# CC3200 register map
Vendor: Texas Instruments; Series: SimpleLink; File version: 1.0
CPU: CM4 r0p1, little endian, MPU, no FPU, 3 interrupt priority bits
Registers are 32-bit, read-write, reset 0x0 unless marked. A register's access mark holds for its fields unless they carry their own. Offsets are from the block's base; [hi:lo] are bit positions; {n}, {i} and the like mark numbered series.

## OCP_SHARED
Base 0x4402E000
0x00 SEMAPHORE1 — OCP_SHARED_SEMAPHORE1
  [1:0] MEM_SEMAPHORE1_M — OCP_SHARED_SEMAPHORE1
  [1:0] _MEM_SEMAPHORE10_M — OCP_SHARED_SEMAPHORE1
  [1:0] _MEM_SEMAPHORE11_M — OCP_SHARED_SEMAPHORE1
  [1:0] _MEM_SEMAPHORE12_M — OCP_SHARED_SEMAPHORE1
0x04 SEMAPHORE2 — OCP_SHARED_SEMAPHORE2
  [1:0] MEM_SEMAPHORE2_M
0x08 SEMAPHORE3 — OCP_SHARED_SEMAPHORE3
  [1:0] MEM_SEMAPHORE3_M
0x0C SEMAPHORE4 — OCP_SHARED_SEMAPHORE4
  [1:0] MEM_SEMAPHORE4_M
0x10 SEMAPHORE5 — OCP_SHARED_SEMAPHORE5
  [1:0] MEM_SEMAPHORE5_M
0x14 SEMAPHORE6 — OCP_SHARED_SEMAPHORE6
  [1:0] MEM_SEMAPHORE6_M
0x18 SEMAPHORE7 — OCP_SHARED_SEMAPHORE7
  [1:0] MEM_SEMAPHORE7_M
0x1C SEMAPHORE8 — OCP_SHARED_SEMAPHORE8
  [1:0] MEM_SEMAPHORE8_M
0x20 SEMAPHORE9 — OCP_SHARED_SEMAPHORE9
  [1:0] MEM_SEMAPHORE9_M
0x24 SEMAPHORE10 — OCP_SHARED_SEMAPHORE10
  [1:0] MEM_SEMAPHORE10_M
0x28 SEMAPHORE11 — OCP_SHARED_SEMAPHORE11
  [1:0] MEM_SEMAPHORE11_M
0x2C SEMAPHORE12 — OCP_SHARED_SEMAPHORE12
  [1:0] MEM_SEMAPHORE12_M
0x30 IC_LOCKER_ID — OCP_SHARED_IC_LOCKER_ID
  [2:0] MEM_IC_LOCKER_ID_M
0x34 MCU_SEMAPHORE_PEND — OCP_SHARED_MCU_SEMAPHORE_PEND
  [15:0] MEM_MCU_SEMAPHORE_PEND_M
0x38 WL_SEMAPHORE_PEND — OCP_SHARED_WL_SEMAPHORE_PEND
  [15:0] MEM_WL_SEMAPHORE_PEND_M
0x3C PLATFORM_DETECTION_RD_ONLY — OCP_SHARED_PLATFORM_DETECTION_RD_ONLY
  [15:0] PLATFORM_DETECTION_M
0x40 SEMAPHORES_STATUS_RD_ONLY — OCP_SHARED_SEMAPHORES_STATUS_RD_ONLY
  [11:0] SEMAPHORES_STATUS_M
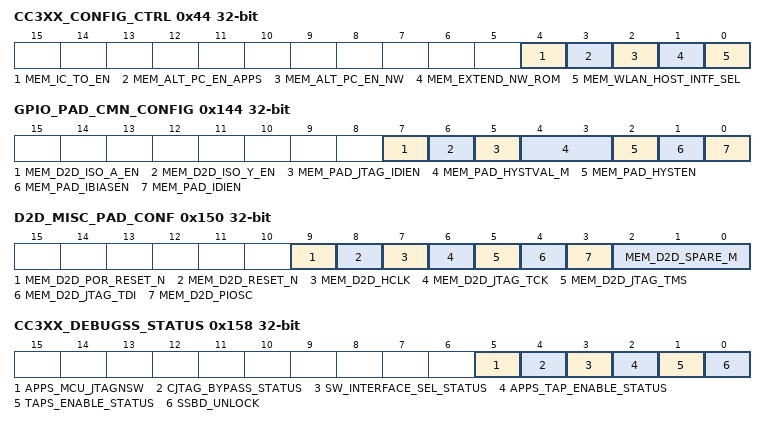
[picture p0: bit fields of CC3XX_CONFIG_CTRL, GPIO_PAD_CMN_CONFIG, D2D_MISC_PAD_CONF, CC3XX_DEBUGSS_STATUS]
0x44 CC3XX_CONFIG_CTRL — OCP_SHARED_CC3XX_CONFIG_CTRL
  [4] MEM_IC_TO_EN — OCP_SHARED_CC3XX_CONFIG_CTRL
  [3] MEM_ALT_PC_EN_APPS — OCP_SHARED_CC3XX_CONFIG_CTRL
  [2] MEM_ALT_PC_EN_NW — OCP_SHARED_CC3XX_CONFIG_CTRL
  [1] MEM_EXTEND_NW_ROM — OCP_SHARED_CC3XX_CONFIG_CTRL
  [0] MEM_WLAN_HOST_INTF_SEL — OCP_SHARED_CC3XX_CONFIG_CTRL
0x48 CC3XX_SHARED_MEM_SEL_LSB — OCP_SHARED_CC3XX_SHARED_MEM_SEL_LSB
  [29:0] MEM_SHARED_MEM_SEL_LSB_M
0x4C CC3XX_SHARED_MEM_SEL_MSB — OCP_SHARED_CC3XX_SHARED_MEM_SEL_MSB
  [11:0] MEM_SHARED_MEM_SEL_MSB_M
0x50 WLAN_ELP_WAKE_EN — OCP_SHARED_WLAN_ELP_WAKE_EN
  [0] MEM_WLAN_ELP_WAKE_EN
0x54 DEVINIT_ROM_START_ADDR — OCP_SHARED_DEVINIT_ROM_START_ADDR
  [31:0] MEM_DEVINIT_ROM_START_ADDR_M
0x58 DEVINIT_ROM_END_ADDR — OCP_SHARED_DEVINIT_ROM_END_ADDR
  [31:0] MEM_DEVINIT_ROM_END_ADDR_M
0x5C SSBD_SEED — OCP_SHARED_SSBD_SEED
  [31:0] MEM_SSBD_SEED_M
0x60 SSBD_CHK — OCP_SHARED_SSBD_CHK
  [31:0] MEM_SSBD_CHK_M
0x64 SSBD_POLY_SEL — OCP_SHARED_SSBD_POLY_SEL
  [1:0] MEM_SSBD_POLY_SEL_M
{0x68+4i} SPARE_REG_{i} (i=0..3) — OCP_SHARED_SPARE_REG_{i}
  [31:0] MEM_SPARE_REG_{i}_M
0xA0 GPIO_PAD_CONFIG_0 — OCP_SHARED_GPIO_PAD_CONFIG_0
  [11:0] MEM_GPIO_PAD_CONFIG_0_M
0xA4 GPIO_PAD_CONFIG_1 — OCP_SHARED_GPIO_PAD_CONFIG_1
  [11:0] MEM_GPIO_PAD_CONFIG_1_M — OCP_SHARED_GPIO_PAD_CONFIG_1
  [11:0] _MEM_GPIO_PAD_CONFIG_{n}_M (n=10..19) — OCP_SHARED_GPIO_PAD_CONFIG_1
0xA8 GPIO_PAD_CONFIG_2 — OCP_SHARED_GPIO_PAD_CONFIG_2
  [11:0] MEM_GPIO_PAD_CONFIG_2_M — OCP_SHARED_GPIO_PAD_CONFIG_2
  [11:0] _MEM_GPIO_PAD_CONFIG_{n}_M (n=20..29) — OCP_SHARED_GPIO_PAD_CONFIG_2
0xAC GPIO_PAD_CONFIG_3 — OCP_SHARED_GPIO_PAD_CONFIG_3
  [11:0] MEM_GPIO_PAD_CONFIG_3_M — OCP_SHARED_GPIO_PAD_CONFIG_3
  [11:0] _MEM_GPIO_PAD_CONFIG_30_M — OCP_SHARED_GPIO_PAD_CONFIG_3
  [11:0] _MEM_GPIO_PAD_CONFIG_31_M — OCP_SHARED_GPIO_PAD_CONFIG_3
  [11:0] _MEM_GPIO_PAD_CONFIG_32_M — OCP_SHARED_GPIO_PAD_CONFIG_3
  [5:0] _MEM_GPIO_PAD_CONFIG_{n}_M (n=33..39) — OCP_SHARED_GPIO_PAD_CONFIG_3
0xB0 GPIO_PAD_CONFIG_4 — OCP_SHARED_GPIO_PAD_CONFIG_4
  [11:0] MEM_GPIO_PAD_CONFIG_4_M — OCP_SHARED_GPIO_PAD_CONFIG_4
  [18:0] _MEM_GPIO_PAD_CONFIG_40_M — OCP_SHARED_GPIO_PAD_CONFIG_4
{0xA0+4i} GPIO_PAD_CONFIG_{i} (i=5..32) — OCP_SHARED_GPIO_PAD_CONFIG_{i}
  [11:0] MEM_GPIO_PAD_CONFIG_{i}_M
{0xA0+4i} GPIO_PAD_CONFIG_{i} (i=33..39) — OCP_SHARED_GPIO_PAD_CONFIG_{i}
  [5:0] MEM_GPIO_PAD_CONFIG_{i}_M
0x140 GPIO_PAD_CONFIG_40 — OCP_SHARED_GPIO_PAD_CONFIG_40
  [18:0] MEM_GPIO_PAD_CONFIG_40_M
0x144 GPIO_PAD_CMN_CONFIG — OCP_SHARED_GPIO_PAD_CMN_CONFIG
  [7] MEM_D2D_ISO_A_EN — OCP_SHARED_GPIO_PAD_CMN_CONFIG
  [6] MEM_D2D_ISO_Y_EN — OCP_SHARED_GPIO_PAD_CMN_CONFIG
  [5] MEM_PAD_JTAG_IDIEN — OCP_SHARED_GPIO_PAD_CMN_CONFIG
  [4:3] MEM_PAD_HYSTVAL_M — OCP_SHARED_GPIO_PAD_CMN_CONFIG
  [2] MEM_PAD_HYSTEN — OCP_SHARED_GPIO_PAD_CMN_CONFIG
  [1] MEM_PAD_IBIASEN — OCP_SHARED_GPIO_PAD_CMN_CONFIG
  [0] MEM_PAD_IDIEN — OCP_SHARED_GPIO_PAD_CMN_CONFIG
0x148 D2D_DEV_PAD_CMN_CONFIG — OCP_SHARED_D2D_DEV_PAD_CMN_CONFIG
  [5:0] MEM_DEV_PAD_CMN_CONF_M
0x14C D2D_TOSTACK_PAD_CONF — OCP_SHARED_D2D_TOSTACK_PAD_CONF
  [28:0] MEM_D2D_TOSTACK_PAD_CONF_M
0x150 D2D_MISC_PAD_CONF — OCP_SHARED_D2D_MISC_PAD_CONF
  [9] MEM_D2D_POR_RESET_N — OCP_SHARED_D2D_MISC_PAD_CONF
  [8] MEM_D2D_RESET_N — OCP_SHARED_D2D_MISC_PAD_CONF
  [7] MEM_D2D_HCLK — OCP_SHARED_D2D_MISC_PAD_CONF
  [6] MEM_D2D_JTAG_TCK — OCP_SHARED_D2D_MISC_PAD_CONF
  [5] MEM_D2D_JTAG_TMS — OCP_SHARED_D2D_MISC_PAD_CONF
  [4] MEM_D2D_JTAG_TDI — OCP_SHARED_D2D_MISC_PAD_CONF
  [3] MEM_D2D_PIOSC — OCP_SHARED_D2D_MISC_PAD_CONF
  [2:0] MEM_D2D_SPARE_M — OCP_SHARED_D2D_MISC_PAD_CONF
0x154 SOP_CONF_OVERRIDE — OCP_SHARED_SOP_CONF_OVERRIDE
  [0] MEM_SOP_CONF_OVERRIDE
0x158 CC3XX_DEBUGSS_STATUS — OCP_SHARED_CC3XX_DEBUGSS_STATUS
  [5] APPS_MCU_JTAGNSW — OCP_SHARED_CC3XX_DEBUGSS_STATUS
  [4] CJTAG_BYPASS_STATUS — OCP_SHARED_CC3XX_DEBUGSS_STATUS
  [3] SW_INTERFACE_SEL_STATUS — OCP_SHARED_CC3XX_DEBUGSS_STATUS
  [2] APPS_TAP_ENABLE_STATUS — OCP_SHARED_CC3XX_DEBUGSS_STATUS
  [1] TAPS_ENABLE_STATUS — OCP_SHARED_CC3XX_DEBUGSS_STATUS
  [0] SSBD_UNLOCK — OCP_SHARED_CC3XX_DEBUGSS_STATUS
0x15C CC3XX_DEBUGMUX_SEL — OCP_SHARED_CC3XX_DEBUGMUX_SEL
  [15:0] MEM_CC3XX_DEBUGMUX_SEL_M
0x160 ALT_PC_VAL_NW — OCP_SHARED_ALT_PC_VAL_NW
  [31:0] MEM_ALT_PC_VAL_NW_M
0x164 ALT_PC_VAL_APPS — OCP_SHARED_ALT_PC_VAL_APPS
  [31:0] MEM_ALT_PC_VAL_APPS_M
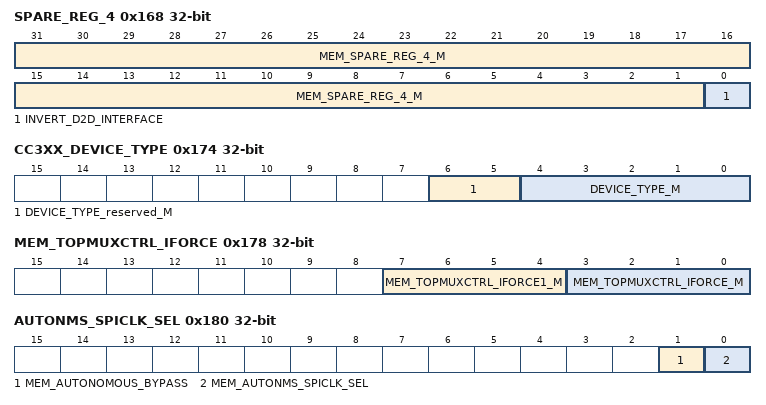
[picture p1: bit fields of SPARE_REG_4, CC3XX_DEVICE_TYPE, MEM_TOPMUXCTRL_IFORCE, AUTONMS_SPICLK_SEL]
0x168 SPARE_REG_4 — OCP_SHARED_SPARE_REG_4
  [31:1] MEM_SPARE_REG_4_M — OCP_SHARED_SPARE_REG_4
  [0] INVERT_D2D_INTERFACE — OCP_SHARED_SPARE_REG_4
0x16C SPARE_REG_5 — OCP_SHARED_SPARE_REG_5
  [31:0] MEM_SPARE_REG_5_M
0x170 SH_SPI_CS_MASK — OCP_SHARED_SH_SPI_CS_MASK
  [3:0] MEM_SH_SPI_CS_MASK_M
0x174 CC3XX_DEVICE_TYPE — OCP_SHARED_CC3XX_DEVICE_TYPE
  [6:5] DEVICE_TYPE_reserved_M — OCP_SHARED_CC3XX_DEVICE_TYPE
  [4:0] DEVICE_TYPE_M — OCP_SHARED_CC3XX_DEVICE_TYPE
0x178 MEM_TOPMUXCTRL_IFORCE — OCP_SHARED_MEM_TOPMUXCTRL_IFORCE
  [7:4] MEM_TOPMUXCTRL_IFORCE1_M — OCP_SHARED_MEM_TOPMUXCTRL_IFORCE
  [3:0] MEM_TOPMUXCTRL_IFORCE_M — OCP_SHARED_MEM_TOPMUXCTRL_IFORCE
0x17C CC3XX_DEV_PACKAGE_DETECT — OCP_SHARED_CC3XX_DEV_PACKAGE_DETECT
  [0] DEV_PKG_DETECT
0x180 AUTONMS_SPICLK_SEL — OCP_SHARED_AUTONMS_SPICLK_SEL
  [1] MEM_AUTONOMOUS_BYPASS — OCP_SHARED_AUTONMS_SPICLK_SEL
  [0] MEM_AUTONMS_SPICLK_SEL — OCP_SHARED_AUTONMS_SPICLK_SEL
0x184 CC3XX_DEV_PADCONF — OCP_SHARED_CC3XX_DEV_PADCONF
  [15:0] MEM_CC3XX_DEV_PADCONF_M
0x188 SPARE_REG_8 — OCP_SHARED_SPARE_REG_8
0x18C SPARE_REG_6 — OCP_SHARED_SPARE_REG_6
  [31:0] MEM_SPARE_REG_6_M
0x190 SPARE_REG_7 — OCP_SHARED_SPARE_REG_7
  [31:0] MEM_SPARE_REG_7_M
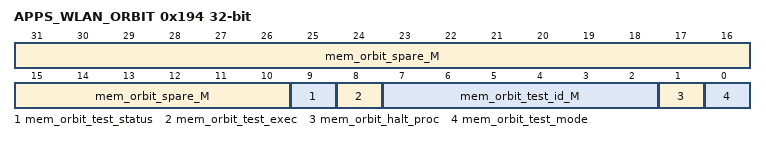
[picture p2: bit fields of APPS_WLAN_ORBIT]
0x194 APPS_WLAN_ORBIT — OCP_SHARED_APPS_WLAN_ORBIT
  [31:10] mem_orbit_spare_M — OCP_SHARED_APPS_WLAN_ORBIT
  [9] mem_orbit_test_status — OCP_SHARED_APPS_WLAN_ORBIT
  [8] mem_orbit_test_exec — OCP_SHARED_APPS_WLAN_ORBIT
  [7:2] mem_orbit_test_id_M — OCP_SHARED_APPS_WLAN_ORBIT
  [1] mem_orbit_halt_proc — OCP_SHARED_APPS_WLAN_ORBIT
  [0] mem_orbit_test_mode — OCP_SHARED_APPS_WLAN_ORBIT
0x198 APPS_WLAN_SCRATCH_PAD — OCP_SHARED_APPS_WLAN_SCRATCH_PAD
  [31:0] MEM_APPS_WLAN_SCRATCH_PAD_M
